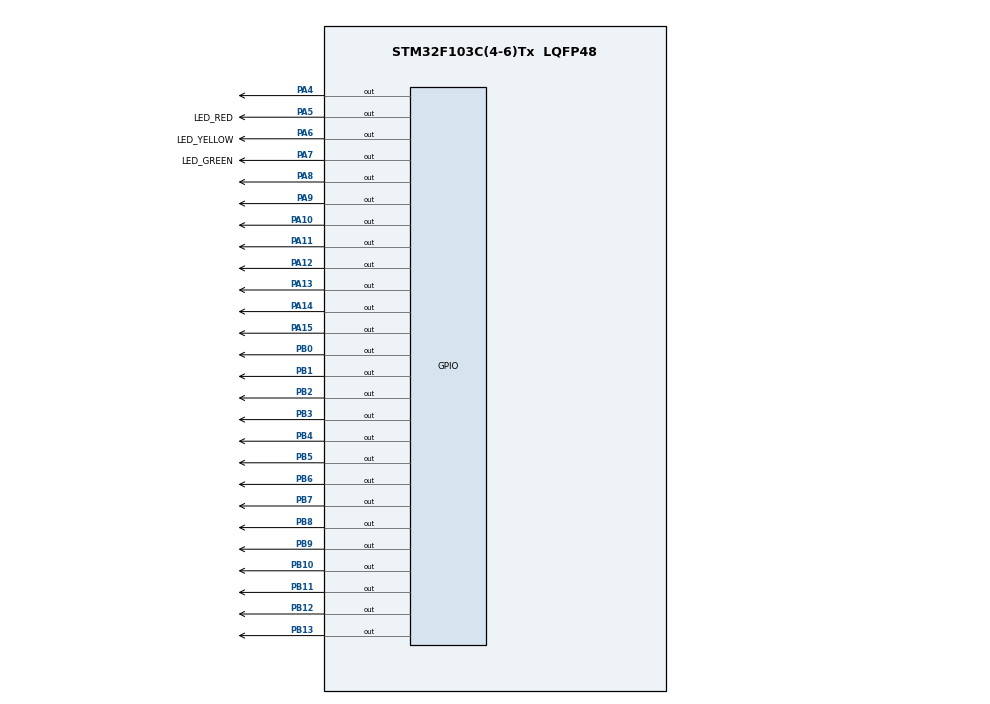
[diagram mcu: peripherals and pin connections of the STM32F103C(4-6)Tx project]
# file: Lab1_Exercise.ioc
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Mcu.Family=STM32F1
Mcu.Name=STM32F103C(4-6)Tx
Mcu.Package=LQFP48
NVIC.PriorityGroup=NVIC_PRIORITYGROUP_4
PA10.Signal=GPIO_Output
PA11.Signal=GPIO_Output
PA12.Signal=GPIO_Output
PA13.Signal=GPIO_Output
PA14.Signal=GPIO_Output
PA15.Signal=GPIO_Output
PA4.Signal=GPIO_Output
PA5.GPIO_Label=LED_RED
PA5.Signal=GPIO_Output
PA6.GPIO_Label=LED_YELLOW
PA6.Signal=GPIO_Output
PA7.GPIO_Label=LED_GREEN
PA7.Signal=GPIO_Output
PA8.Signal=GPIO_Output
PA9.Signal=GPIO_Output
PB0.Signal=GPIO_Output
PB1.Signal=GPIO_Output
PB10.Signal=GPIO_Output
PB11.Signal=GPIO_Output
PB12.Signal=GPIO_Output
PB13.Signal=GPIO_Output
PB2.Signal=GPIO_Output
PB3.Signal=GPIO_Output
PB4.Signal=GPIO_Output
PB5.Signal=GPIO_Output
PB6.Signal=GPIO_Output
PB7.Signal=GPIO_Output
PB8.Signal=GPIO_Output
PB9.Signal=GPIO_Output
ProjectManager.HeapSize=0x200
ProjectManager.StackSize=0x400
ProjectManager.TargetToolchain=STM32CubeIDE
RCC.APB1Freq_Value=8000000
RCC.APB2Freq_Value=8000000
VP_SYS_VS_ND.Mode=No_Debug
board=custom

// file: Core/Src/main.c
/* USER CODE BEGIN Header */
/**
  ******************************************************************************
  * @file           : main.c
  * @brief          : Main program body
  ******************************************************************************
  * @attention
  *
  * <h2><center>&copy; Copyright (c) 2026 STMicroelectronics.
  * All rights reserved.</center></h2>
  *
  * This software component is licensed by ST under BSD 3-Clause license,
  * the "License"; You may not use this file except in compliance with the
  * License. You may obtain a copy of the License at:
  *                        opensource.org/licenses/BSD-3-Clause
  *
  ******************************************************************************
  */
/* USER CODE END Header */
#include "main.h"

void SystemClock_Config(void);
static void MX_GPIO_Init(void);

int main(void)
{

  /* MCU Configuration--------------------------------------------------------*/

  /* Reset of all peripherals, Initializes the Flash interface and the Systick. */
  HAL_Init();

  /* Configure the system clock */
  SystemClock_Config();

  /* Initialize all configured peripherals */
  MX_GPIO_Init();
  /* USER CODE BEGIN 2 */
//  HAL_GPIO_WritePin(GPIOA, GPIO_PIN_5, GPIO_PIN_SET);
//  HAL_GPIO_WritePin(GPIOA, GPIO_PIN_6, GPIO_PIN_RESET);
  /* USER CODE END 2 */
  // 1. Định nghĩa struct chứa thông tin Chân và Port GPIO
  typedef struct {
      GPIO_TypeDef* port;
      uint16_t pin;
  } LED_Clock;

  // 2. Khai báo mảng 12 LED đồng hồ dùng chung từ PA4 đến PA15
  static const LED_Clock clock_leds[12] = {
      {GPIOA, GPIO_PIN_6},   // Vị trí 0
      {GPIOA, GPIO_PIN_7},   // Vị trí 1
      {GPIOA, GPIO_PIN_4},   // Vị trí 2
	    {GPIOA, GPIO_PIN_8},   // Vị trí 3
      {GPIOA, GPIO_PIN_9},   // Vị trí 4
      {GPIOA, GPIO_PIN_10},  // Vị trí 5
      {GPIOA, GPIO_PIN_11},  // Vị trí 6
      {GPIOA, GPIO_PIN_12},  // Vị trí 7
      {GPIOA, GPIO_PIN_13},  // Vị trí 8
      {GPIOA, GPIO_PIN_14},  // Vị trí 9
      {GPIOA, GPIO_PIN_15},   // Vị trí 10
      {GPIOA, GPIO_PIN_5}    // Vị trí 11
  };
  /* USER CODE BEGIN PFP */
  // Exercise 7: Tắt toàn bộ 12 LED đồng hồ
  void clearAllClock(void) {
      for (int i = 0; i < 12; i++) {
          // Xuất mức HIGH (SET) để TẮT LED (mạch Active Low)
          HAL_GPIO_WritePin(clock_leds[i].port, clock_leds[i].pin, GPIO_PIN_RESET);
      }
  }

  // Exercise 8: Bật 1 LED tại vị trí num (từ 0 đến 11)
  void setNumberOnClock(int num) {
      if (num >= 0 && num <= 11) {
          // Xuất mức HIGH
          HAL_GPIO_WritePin(clock_leds[num].port, clock_leds[num].pin, GPIO_PIN_SET);
      }
  }

  // Exercise 9: Tắt 1 LED tại vị trí num (từ 0 đến 11)
  void clearNumberOnClock(int num) {
      if (num >= 0 && num <= 11) {
          // Xuất mức HIGH (SET) để TẮT LED
          HAL_GPIO_WritePin(clock_leds[num].port, clock_leds[num].pin, GPIO_PIN_RESET);
      }
  }
  /* USER CODE END PFP */
  /* Infinite loop */
  /* USER CODE BEGIN WHILE */
  int hour = 0;
  int minute = 0;
  int second = 0;
  while (1)
  {
    /* USER CODE END WHILE */
	     //Xóa toàn bộ LED trước
      clearAllClock();

      // Tính toán vị trí LED từ 0 đến 11
      int hour_pos   = hour % 12;
      int minute_pos = minute / 5 ;
      int second_pos = second / 5 ;

      // Bật 3 LED tương ứng Giờ, Phút, Giây
      setNumberOnClock(hour_pos);
      setNumberOnClock(minute_pos);
      setNumberOnClock(second_pos);

      // Dừng 1 giây
      HAL_Delay(1000);

      // Tăng dần
      second++;
      if (second >= 60) {
          second = 0;
          minute++;
        }

      if (minute >= 60) {
          minute = 0;
          hour++;
        }

      if (hour >= 12) {
          hour = 0;
      }
  }
}

void SystemClock_Config(void)
{
  RCC_OscInitTypeDef RCC_OscInitStruct = {0};
  RCC_ClkInitTypeDef RCC_ClkInitStruct = {0};

  /** Initializes the RCC Oscillators according to the specified parameters
  * in the RCC_OscInitTypeDef structure.
  */
  RCC_OscInitStruct.OscillatorType = RCC_OSCILLATORTYPE_HSI;
  RCC_OscInitStruct.HSIState = RCC_HSI_ON;
  RCC_OscInitStruct.HSICalibrationValue = RCC_HSICALIBRATION_DEFAULT;
  RCC_OscInitStruct.PLL.PLLState = RCC_PLL_NONE;
  if (HAL_RCC_OscConfig(&RCC_OscInitStruct) != HAL_OK)
  {
    Error_Handler();
  }
  /** Initializes the CPU, AHB and APB buses clocks
  */
  RCC_ClkInitStruct.ClockType = RCC_CLOCKTYPE_HCLK|RCC_CLOCKTYPE_SYSCLK
                              |RCC_CLOCKTYPE_PCLK1|RCC_CLOCKTYPE_PCLK2;
  RCC_ClkInitStruct.SYSCLKSource = RCC_SYSCLKSOURCE_HSI;
  RCC_ClkInitStruct.AHBCLKDivider = RCC_SYSCLK_DIV1;
  RCC_ClkInitStruct.APB1CLKDivider = RCC_HCLK_DIV1;
  RCC_ClkInitStruct.APB2CLKDivider = RCC_HCLK_DIV1;

  if (HAL_RCC_ClockConfig(&RCC_ClkInitStruct, FLASH_LATENCY_0) != HAL_OK)
  {
    Error_Handler();
  }
}

static void MX_GPIO_Init(void)
{
  GPIO_InitTypeDef GPIO_InitStruct = {0};

  /* GPIO Ports Clock Enable */
  __HAL_RCC_GPIOA_CLK_ENABLE();

  /*Configure GPIO pin Output Level */
  HAL_GPIO_WritePin(GPIOA, GPIO_PIN_4|LED_RED_Pin|LED_YELLOW_Pin|LED_GREEN_Pin
                          |GPIO_PIN_8|GPIO_PIN_9|GPIO_PIN_10|GPIO_PIN_11
                          |GPIO_PIN_12|GPIO_PIN_13|GPIO_PIN_14|GPIO_PIN_15, GPIO_PIN_RESET);

  /*Configure GPIO pins : PA4 LED_RED_Pin LED_YELLOW_Pin LED_GREEN_Pin
                           PA8 PA9 PA10 PA11
                           PA12 PA13 PA14 PA15 */
  GPIO_InitStruct.Pin = GPIO_PIN_4|LED_RED_Pin|LED_YELLOW_Pin|LED_GREEN_Pin
                          |GPIO_PIN_8|GPIO_PIN_9|GPIO_PIN_10|GPIO_PIN_11
                          |GPIO_PIN_12|GPIO_PIN_13|GPIO_PIN_14|GPIO_PIN_15;
  GPIO_InitStruct.Mode = GPIO_MODE_OUTPUT_PP;
  GPIO_InitStruct.Pull = GPIO_NOPULL;
  GPIO_InitStruct.Speed = GPIO_SPEED_FREQ_LOW;
  HAL_GPIO_Init(GPIOA, &GPIO_InitStruct);

}

/* USER CODE BEGIN 4 */
// Exercise 7: Tắt toàn bộ 12 LED đồng hồ

/* USER CODE END 4 */

void Error_Handler(void)
{
  __disable_irq();
  while (1)
  {
  }
}

/************************ (C) COPYRIGHT STMicroelectronics *****END OF FILE****/
